# iostm32f105xx register map
Registers are 32-bit, access not given, no defined reset value unless marked. A register's access mark holds for its fields unless they carry their own. Addresses are absolute; registers are grouped by the start of their names; [hi:lo] are bit positions; {n}, {i} and the like mark numbered series.

## TIM4
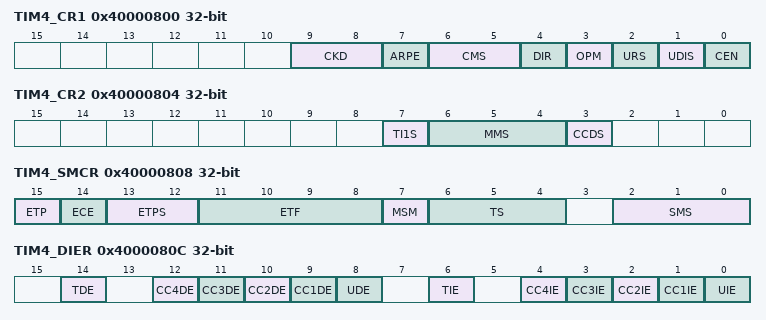
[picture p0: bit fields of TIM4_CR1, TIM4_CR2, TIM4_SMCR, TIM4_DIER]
0x40000800 TIM4_CR1
  [9:8] CKD, [7] ARPE, [6:5] CMS, [4] DIR, [3] OPM, [2] URS, [1] UDIS, [0] CEN
0x40000804 TIM4_CR2
  [7] TI1S, [6:4] MMS, [3] CCDS
0x40000808 TIM4_SMCR
  [15] ETP, [14] ECE, [13:12] ETPS, [11:8] ETF, [7] MSM, [6:4] TS, [2:0] SMS
0x4000080C TIM4_DIER
  [14] TDE, [n+8] CC{n}DE (n=1..4), [8] UDE, [6] TIE, [n] CC{n}IE (n=1..4), [0] UIE
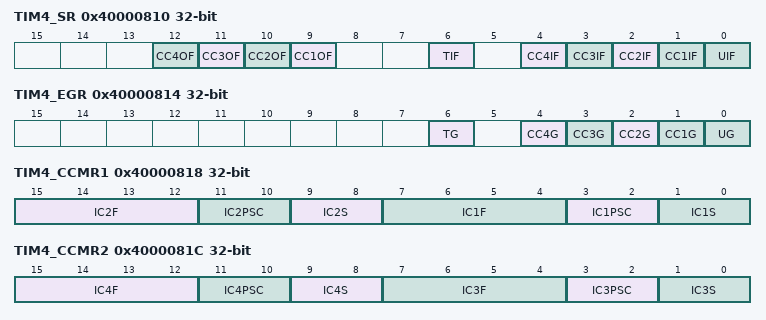
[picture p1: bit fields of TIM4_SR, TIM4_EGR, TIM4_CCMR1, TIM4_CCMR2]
0x40000810 TIM4_SR
  [n+8] CC{n}OF (n=1..4), [6] TIF, [n] CC{n}IF (n=1..4), [0] UIF
0x40000814 TIM4_EGR
  [6] TG, [n] CC{n}G (n=1..4), [0] UG
0x40000818 TIM4_CCMR1
  [15:12] IC2F, [11:10] IC2PSC, [9:8] IC2S, [7:4] IC1F, [3:2] IC1PSC, [1:0] IC1S
0x40000818 TIM4_OCMR1
0x4000081C TIM4_CCMR2
  [15:12] IC4F, [11:10] IC4PSC, [9:8] IC4S, [7:4] IC3F, [3:2] IC3PSC, [1:0] IC3S
0x4000081C TIM4_OCMR2
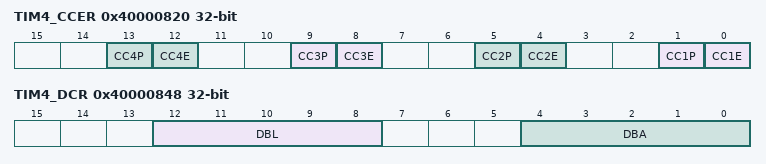
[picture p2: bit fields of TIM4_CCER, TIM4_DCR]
0x40000820 TIM4_CCER
  [4n-3] CC{n}P (n=1..4), [4n-4] CC{n}E (n=1..4)
0x40000824 TIM4_CNT
  [15:0] CNT
0x40000828 TIM4_PSC
  [15:0] PSC
0x4000082C TIM4_ARR
  [15:0] ARR
{0x40000830+4i} TIM4_CCR{i} (i=1..4)
  [15:0] CCR
0x40000848 TIM4_DCR
  [12:8] DBL, [4:0] DBA
0x4000084C TIM4_DMAR
  [15:0] DMAB

## TIM5
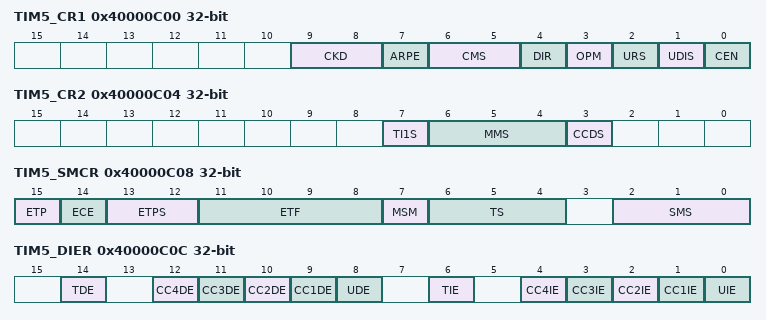
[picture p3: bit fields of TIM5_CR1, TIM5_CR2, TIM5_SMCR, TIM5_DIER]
0x40000C00 TIM5_CR1
  [9:8] CKD, [7] ARPE, [6:5] CMS, [4] DIR, [3] OPM, [2] URS, [1] UDIS, [0] CEN
0x40000C04 TIM5_CR2
  [7] TI1S, [6:4] MMS, [3] CCDS
0x40000C08 TIM5_SMCR
  [15] ETP, [14] ECE, [13:12] ETPS, [11:8] ETF, [7] MSM, [6:4] TS, [2:0] SMS
0x40000C0C TIM5_DIER
  [14] TDE, [n+8] CC{n}DE (n=1..4), [8] UDE, [6] TIE, [n] CC{n}IE (n=1..4), [0] UIE
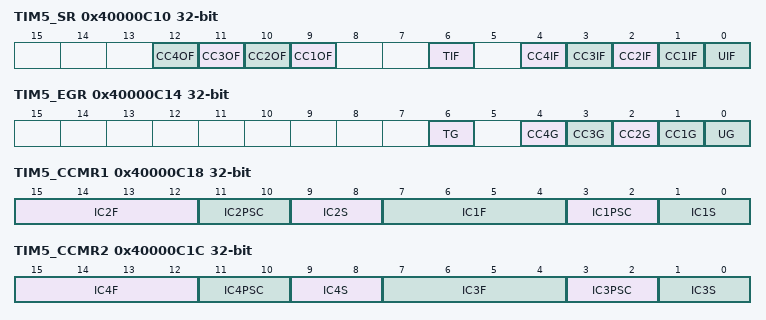
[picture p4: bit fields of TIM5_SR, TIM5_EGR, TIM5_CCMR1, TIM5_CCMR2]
0x40000C10 TIM5_SR
  [n+8] CC{n}OF (n=1..4), [6] TIF, [n] CC{n}IF (n=1..4), [0] UIF
0x40000C14 TIM5_EGR
  [6] TG, [n] CC{n}G (n=1..4), [0] UG
0x40000C18 TIM5_CCMR1
  [15:12] IC2F, [11:10] IC2PSC, [9:8] IC2S, [7:4] IC1F, [3:2] IC1PSC, [1:0] IC1S
0x40000C18 TIM5_OCMR1
0x40000C1C TIM5_CCMR2
  [15:12] IC4F, [11:10] IC4PSC, [9:8] IC4S, [7:4] IC3F, [3:2] IC3PSC, [1:0] IC3S
0x40000C1C TIM5_OCMR2
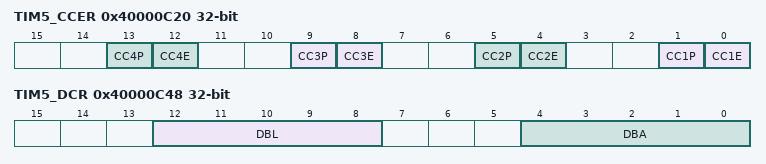
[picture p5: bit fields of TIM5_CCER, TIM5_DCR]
0x40000C20 TIM5_CCER
  [4n-3] CC{n}P (n=1..4), [4n-4] CC{n}E (n=1..4)
0x40000C24 TIM5_CNT
  [15:0] CNT
0x40000C28 TIM5_PSC
  [15:0] PSC
0x40000C2C TIM5_ARR
  [15:0] ARR
{0x40000C30+4i} TIM5_CCR{i} (i=1..4)
  [15:0] CCR
0x40000C48 TIM5_DCR
  [12:8] DBL, [4:0] DBA
0x40000C4C TIM5_DMAR
  [15:0] DMAB

## TIM6
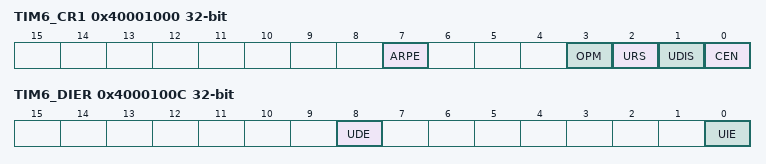
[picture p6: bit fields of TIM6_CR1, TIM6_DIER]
0x40001000 TIM6_CR1
  [7] ARPE, [3] OPM, [2] URS, [1] UDIS, [0] CEN
0x40001004 TIM6_CR2
  [6:4] MMS
0x4000100C TIM6_DIER
  [8] UDE, [0] UIE
0x40001010 TIM6_SR
  [0] UIF
0x40001014 TIM6_EGR
  [0] UG
0x40001024 TIM6_CNT
  [15:0] CNT
0x40001028 TIM6_PSC
  [15:0] PSC
0x4000102C TIM6_ARR
  [15:0] ARR

## TIM7
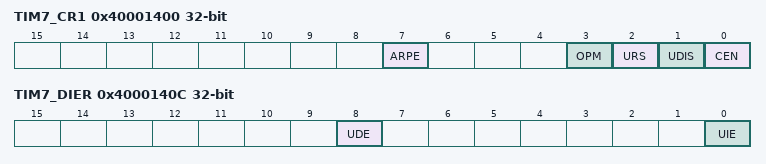
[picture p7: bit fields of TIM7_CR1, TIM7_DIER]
0x40001400 TIM7_CR1
  [7] ARPE, [3] OPM, [2] URS, [1] UDIS, [0] CEN
0x40001404 TIM7_CR2
  [6:4] MMS
0x4000140C TIM7_DIER
  [8] UDE, [0] UIE
0x40001410 TIM7_SR
  [0] UIF
0x40001414 TIM7_EGR
  [0] UG
0x40001424 TIM7_CNT
  [15:0] CNT
0x40001428 TIM7_PSC
  [15:0] PSC
0x4000142C TIM7_ARR
  [15:0] ARR

## CAN1
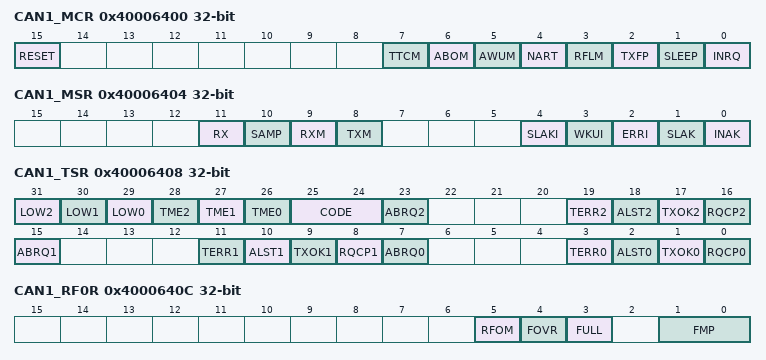
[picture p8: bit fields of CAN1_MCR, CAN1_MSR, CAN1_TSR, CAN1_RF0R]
0x40006400 CAN1_MCR
  [15] RESET, [7] TTCM, [6] ABOM, [5] AWUM, [4] NART, [3] RFLM, [2] TXFP, [1] SLEEP, [0] INRQ
0x40006404 CAN1_MSR
  [11] RX, [10] SAMP, [9] RXM, [8] TXM, [4] SLAKI, [3] WKUI, [2] ERRI, [1] SLAK, [0] INAK
0x40006408 CAN1_TSR
  [31] LOW2, [30] LOW1, [29] LOW0, [28] TME2, [27] TME1, [26] TME0, [25:24] CODE, [23] ABRQ2, [19] TERR2, [18] ALST2, [17] TXOK2, [16] RQCP2, [15] ABRQ1, [11] TERR1, [10] ALST1, [9] TXOK1, [8] RQCP1, [7] ABRQ0, [3] TERR0, [2] ALST0, [1] TXOK0, [0] RQCP0
0x4000640C CAN1_RF0R
  [5] RFOM, [4] FOVR, [3] FULL, [1:0] FMP
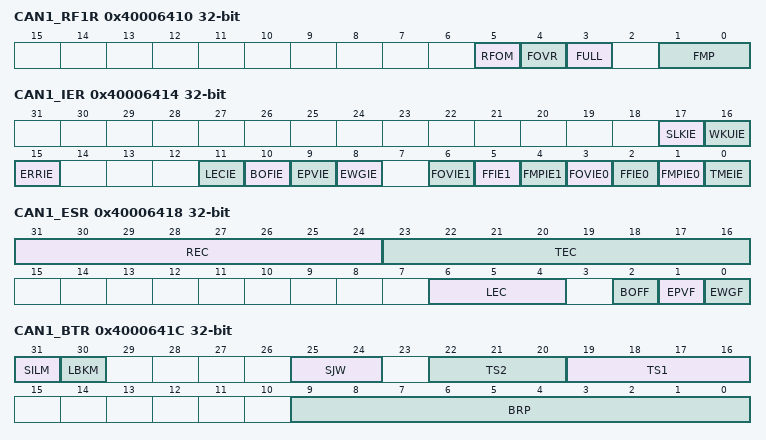
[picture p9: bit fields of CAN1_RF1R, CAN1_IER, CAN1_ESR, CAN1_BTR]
0x40006410 CAN1_RF1R
  [5] RFOM, [4] FOVR, [3] FULL, [1:0] FMP
0x40006414 CAN1_IER
  [17] SLKIE, [16] WKUIE, [15] ERRIE, [11] LECIE, [10] BOFIE, [9] EPVIE, [8] EWGIE, [6] FOVIE1, [5] FFIE1, [4] FMPIE1, [3] FOVIE0, [2] FFIE0, [1] FMPIE0, [0] TMEIE
0x40006418 CAN1_ESR
  [31:24] REC, [23:16] TEC, [6:4] LEC, [2] BOFF, [1] EPVF, [0] EWGF
0x4000641C CAN1_BTR
  [31] SILM, [30] LBKM, [25:24] SJW, [22:20] TS2, [19:16] TS1, [9:0] BRP
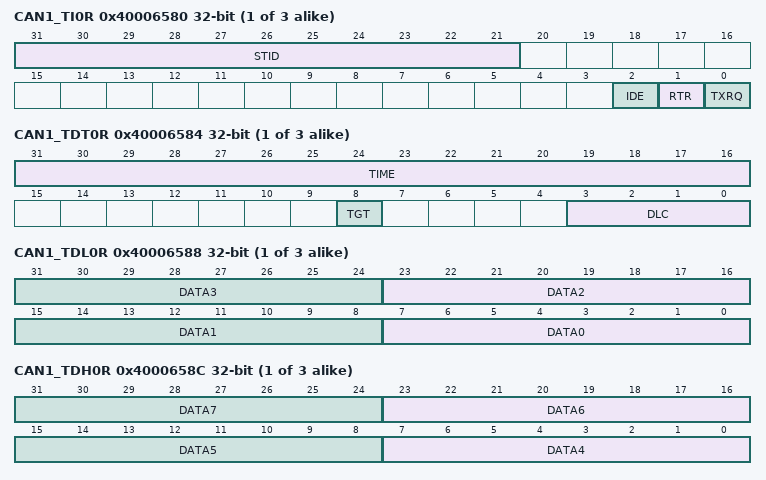
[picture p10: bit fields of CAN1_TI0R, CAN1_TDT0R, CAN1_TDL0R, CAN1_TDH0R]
{0x40006580+0x10*i} CAN1_TI{i}R (i=0..2)
  [31:21] STID, [2] IDE, [1] RTR, [0] TXRQ
{0x40006584+0x10*i} CAN1_TDT{i}R (i=0..2)
  [31:16] TIME, [8] TGT, [3:0] DLC
{0x40006588+0x10*i} CAN1_TDL{i}R (i=0..2)
  [8n+7:8n] DATA{n} (n=0..3)
{0x4000658C+0x10*i} CAN1_TDH{i}R (i=0..2)
  [8n-25:8n-32] DATA{n} (n=4..7)
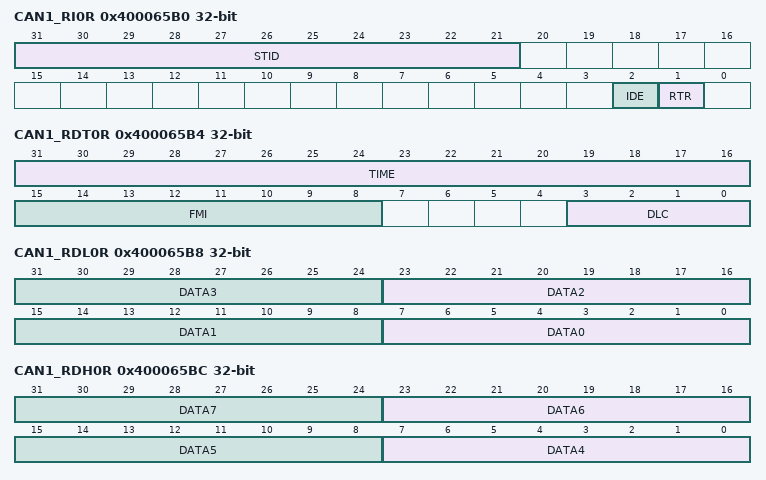
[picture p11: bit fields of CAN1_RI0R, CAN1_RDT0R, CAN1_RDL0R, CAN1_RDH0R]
0x400065B0 CAN1_RI0R
  [31:21] STID, [2] IDE, [1] RTR
0x400065B4 CAN1_RDT0R
  [31:16] TIME, [15:8] FMI, [3:0] DLC
0x400065B8 CAN1_RDL0R
  [8n+7:8n] DATA{n} (n=0..3)
0x400065BC CAN1_RDH0R
  [8n-25:8n-32] DATA{n} (n=4..7)
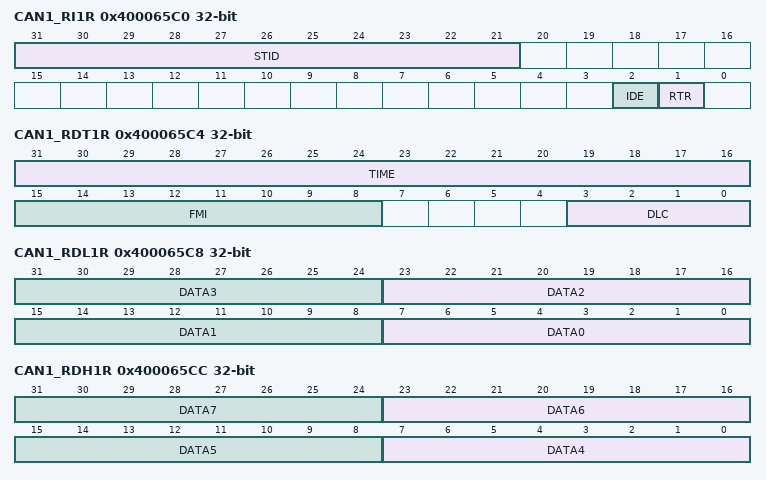
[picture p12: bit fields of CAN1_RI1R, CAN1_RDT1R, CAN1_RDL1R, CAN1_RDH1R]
0x400065C0 CAN1_RI1R
  [31:21] STID, [2] IDE, [1] RTR
0x400065C4 CAN1_RDT1R
  [31:16] TIME, [15:8] FMI, [3:0] DLC
0x400065C8 CAN1_RDL1R
  [8n+7:8n] DATA{n} (n=0..3)
0x400065CC CAN1_RDH1R
  [8n-25:8n-32] DATA{n} (n=4..7)
